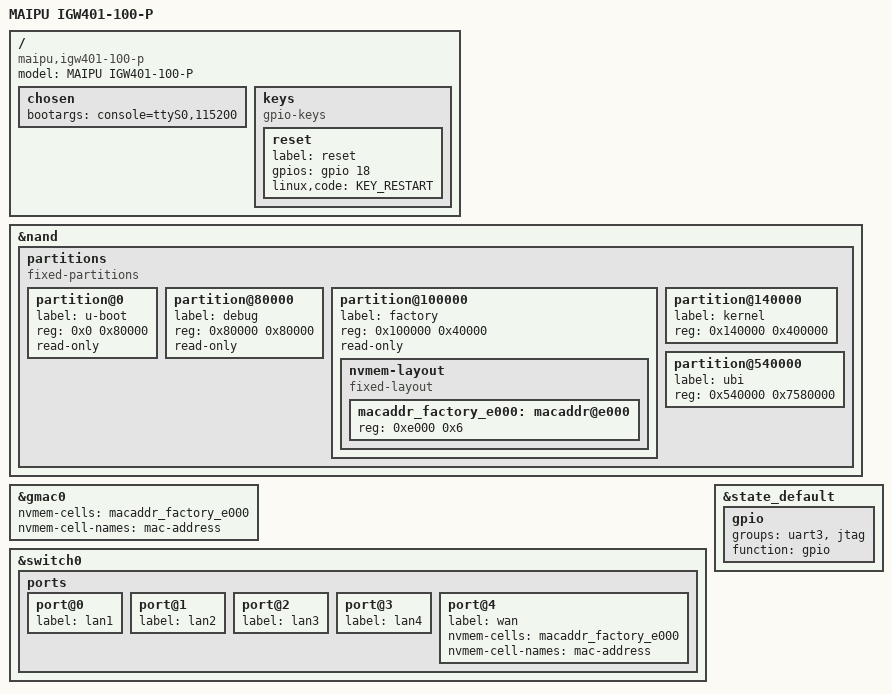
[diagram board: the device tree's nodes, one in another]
#include "mt7621.dtsi"

#include <dt-bindings/gpio/gpio.h>
#include <dt-bindings/input/input.h>
#include <dt-bindings/leds/common.h>

/ {
	compatible = "maipu,igw401-100-p", "mediatek,mt7621-soc";
	model = "MAIPU IGW401-100-P";

	chosen {
		bootargs = "console=ttyS0,115200";
	};

	keys {
		compatible = "gpio-keys";

		reset {
			label = "reset";
			gpios = <&gpio 18 GPIO_ACTIVE_HIGH>;
			linux,code = <KEY_RESTART>;
		};
	};
};

&nand {
	status = "okay";

	partitions {
		compatible = "fixed-partitions";
		#address-cells = <1>;
		#size-cells = <1>;

		partition@0 {
			label = "u-boot";
			reg = <0x0 0x80000>;
			read-only;
		};

		partition@80000 {
			label = "debug";
			reg = <0x80000 0x80000>;
			read-only;
		};

		partition@100000 {
			label = "factory";
			reg = <0x100000 0x40000>;
			read-only;

			nvmem-layout {
				compatible = "fixed-layout";
				#address-cells = <1>;
				#size-cells = <1>;

				macaddr_factory_e000: macaddr@e000 {
					reg = <0xe000 0x6>;
				};
			};
		};

		partition@140000 {
			label = "kernel";
			reg = <0x140000 0x400000>;
		};

		partition@540000 {
			label = "ubi";
			reg = <0x540000 0x7580000>;
		};
	};
};

&gmac0 {
	nvmem-cells = <&macaddr_factory_e000>;
	nvmem-cell-names = "mac-address";
};


&switch0 {
	ports {
		port@0 {
			status = "okay";
			label = "lan1";
		};

		port@1 {
			status = "okay";
			label = "lan2";
		};

		port@2 {
			status = "okay";
			label = "lan3";
		};

		port@3 {
			status = "okay";
			label = "lan4";
		};

		port@4 {
			status = "okay";
			label = "wan";
			nvmem-cells = <&macaddr_factory_e000>;
			nvmem-cell-names = "mac-address";
		};
	};
};

&state_default {
	gpio {
		groups = "uart3", "jtag";
		function = "gpio";
	};
};
